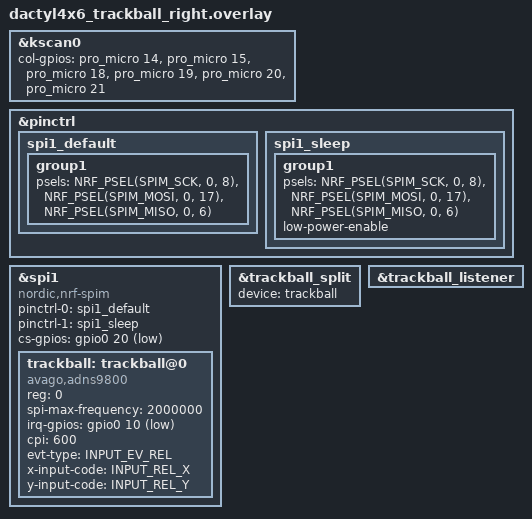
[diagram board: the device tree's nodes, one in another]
#include "dactyl4x6.dtsi"
#include <zephyr/dt-bindings/input/input-event-codes.h>
// #include <dt-bindings/zmk/input_transform.h>

&kscan0 {
    col-gpios
        = <&pro_micro 14 GPIO_ACTIVE_HIGH>
        , <&pro_micro 15 GPIO_ACTIVE_HIGH>
        , <&pro_micro 18 GPIO_ACTIVE_HIGH>
        , <&pro_micro 19 GPIO_ACTIVE_HIGH>
        , <&pro_micro 20 GPIO_ACTIVE_HIGH>
        , <&pro_micro 21 GPIO_ACTIVE_HIGH>
        ;
};

&pinctrl {
    spi1_default: spi1_default {
        group1 {
            psels = <NRF_PSEL(SPIM_SCK, 0, 8)>,
                    <NRF_PSEL(SPIM_MOSI, 0, 17)>,
                    <NRF_PSEL(SPIM_MISO, 0, 6)>;
        };
    };

    spi1_sleep: spi1_sleep {
        group1 {
            psels = <NRF_PSEL(SPIM_SCK, 0, 8)>,
                    <NRF_PSEL(SPIM_MOSI, 0, 17)>,
                    <NRF_PSEL(SPIM_MISO, 0, 6)>;
            low-power-enable;
        };
    };
};

&spi1 {
    status = "okay";
    compatible = "nordic,nrf-spim";
    pinctrl-0 = <&spi1_default>;
    pinctrl-1 = <&spi1_sleep>;
    pinctrl-names = "default", "sleep";
    cs-gpios = <&gpio0 20 GPIO_ACTIVE_LOW>;

    trackball: trackball@0 {
        status = "okay";
        compatible = "avago,adns9800";
        reg = <0>;
        spi-max-frequency = <2000000>;
        irq-gpios = <&gpio0 10 (GPIO_ACTIVE_LOW | GPIO_PULL_UP)>;
        cpi = <600>;
        evt-type = <INPUT_EV_REL>;
        x-input-code = <INPUT_REL_X>;
        y-input-code = <INPUT_REL_Y>;
    };
};

&trackball_split {
    device = <&trackball>;
    // input-processors = <&zip_xy_transform (INPUT_TRANSFORM_XY_SWAP | INPUT_TRANSFORM_X_INVERT | INPUT_TRANSFORM_Y_INVERT)>;

};

&trackball_listener {
    status = "okay";
};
